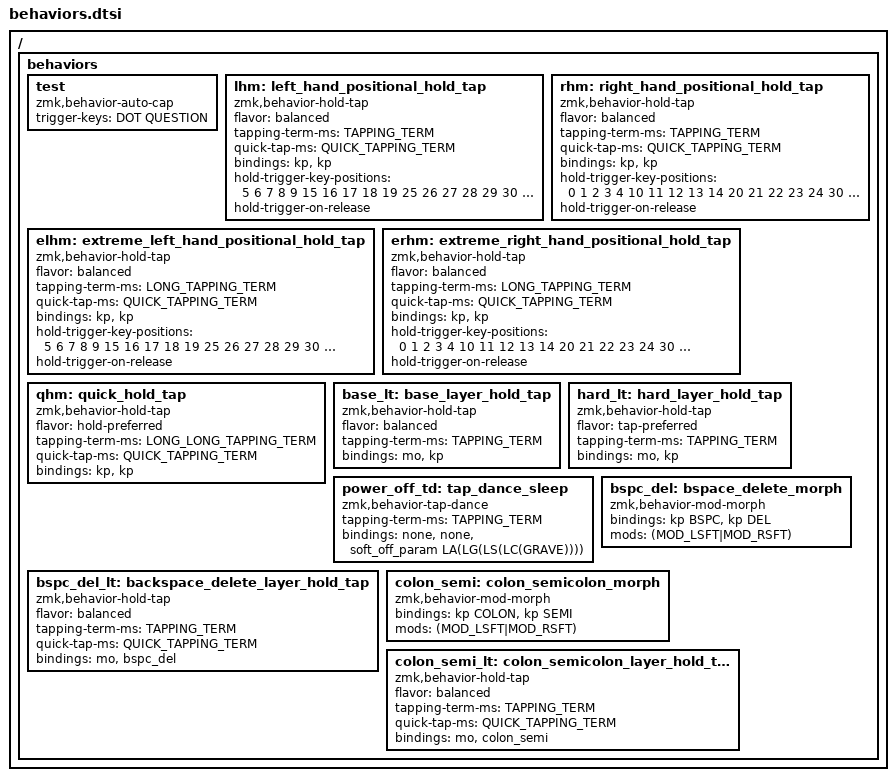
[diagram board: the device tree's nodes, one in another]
/*                KEY POSITIONS

	  ╭────────────────────╮ ╭────────────────────╮
	  │  0   1   2   3   4 │ │  5   6   7   8   9 │
	  │ 10  11  12  13  14 │ │ 15  16  17  18  19 │
	  │ 20  21  22  23  24 │ │ 25  26  27  28  29 │
	  ╰───────╮ 30  31  32 │ │ 33  34  35 ╭───────╯
      		  ╰────────────╯ ╰────────────╯          */

#define TAPPING_TERM 200
#define LONG_TAPPING_TERM 250
#define QUICK_TAPPING_TERM 0
#define LONG_LONG_TAPPING_TERM 500


/ {
	behaviors {
		test: test {
		    compatible = "zmk,behavior-auto-cap";
		    #binding-cells = <0>;
		    trigger-keys = <DOT QUESTION>;
		};

		lhm: left_hand_positional_hold_tap {
		    compatible = "zmk,behavior-hold-tap";
		    #binding-cells = <2>;
		    flavor = "balanced";
		    tapping-term-ms = <TAPPING_TERM>;
		    quick-tap-ms = <QUICK_TAPPING_TERM>;
		    bindings = <&kp>, <&kp>;
		    hold-trigger-key-positions = <5 6 7 8 9 15 16 17 18 19 25 26 27 28 29 30 31 32 33 34 35>;
        hold-trigger-on-release;
		};

		elhm: extreme_left_hand_positional_hold_tap {
		    compatible = "zmk,behavior-hold-tap";
		    #binding-cells = <2>;
		    flavor = "balanced";
		    tapping-term-ms = <LONG_TAPPING_TERM>;
		    quick-tap-ms = <QUICK_TAPPING_TERM>;
		    bindings = <&kp>, <&kp>;
		    hold-trigger-key-positions = <5 6 7 8 9 15 16 17 18 19 25 26 27 28 29 30 31 32 33 34 35>;
        hold-trigger-on-release;
		};

		rhm: right_hand_positional_hold_tap {
		    compatible = "zmk,behavior-hold-tap";
		    #binding-cells = <2>;
		    flavor = "balanced";
		    tapping-term-ms = <TAPPING_TERM>;
		    quick-tap-ms = <QUICK_TAPPING_TERM>;
		    bindings = <&kp>, <&kp>;
		    hold-trigger-key-positions = <0 1 2 3 4 10 11 12 13 14 20 21 22 23 24 30 31 32 33 34 35>;
        hold-trigger-on-release;
		};

		erhm: extreme_right_hand_positional_hold_tap {
		    compatible = "zmk,behavior-hold-tap";
		    #binding-cells = <2>;
		    flavor = "balanced";
		    tapping-term-ms = <LONG_TAPPING_TERM>;
		    quick-tap-ms = <QUICK_TAPPING_TERM>;
		    bindings = <&kp>, <&kp>;
		    hold-trigger-key-positions = <0 1 2 3 4 10 11 12 13 14 20 21 22 23 24 30 31 32 33 34 35>;
        hold-trigger-on-release;
		};

		qhm: quick_hold_tap {
		    compatible = "zmk,behavior-hold-tap";
		    #binding-cells = <2>;
		    flavor = "hold-preferred";
		    tapping-term-ms = <LONG_LONG_TAPPING_TERM>;
		    quick-tap-ms = <QUICK_TAPPING_TERM>;
		    bindings = <&kp>, <&kp>;
		};

		base_lt: base_layer_hold_tap {
		    compatible = "zmk,behavior-hold-tap";
		    #binding-cells = <2>;
		    flavor = "balanced";
		    tapping-term-ms = <TAPPING_TERM>;
		    bindings = <&mo>, <&kp>;
		};

		hard_lt: hard_layer_hold_tap {
		    compatible = "zmk,behavior-hold-tap";
		    #binding-cells = <2>;
		    flavor = "tap-preferred";
		    tapping-term-ms = <TAPPING_TERM>;
		    bindings = <&mo>, <&kp>;
		};

		power_off_td: tap_dance_sleep {
		    compatible = "zmk,behavior-tap-dance";
		    #binding-cells = <0>;
		    tapping-term-ms = <TAPPING_TERM>;
		    bindings = <&none>, <&none>, <&soft_off_param LA(LG(LS(LC(GRAVE))))>;
		};

		bspc_del: bspace_delete_morph {
		    compatible = "zmk,behavior-mod-morph";
		    #binding-cells = <0>;
		    bindings = <&kp BSPC>, <&kp DEL>;
		    mods = <(MOD_LSFT|MOD_RSFT)>;
		};

		bspc_del_lt: backspace_delete_layer_hold_tap {
		    compatible = "zmk,behavior-hold-tap";
		    #binding-cells = <2>;
		    flavor = "balanced";
		    tapping-term-ms = <TAPPING_TERM>;
		    quick-tap-ms = <QUICK_TAPPING_TERM>;
		    bindings = <&mo>, <&bspc_del>;
		};

		colon_semi: colon_semicolon_morph {
		    compatible = "zmk,behavior-mod-morph";
		    #binding-cells = <0>;
		    bindings = <&kp COLON>, <&kp SEMI>;
		    mods = <(MOD_LSFT|MOD_RSFT)>;
		};

		colon_semi_lt: colon_semicolon_layer_hold_tap {
		    compatible = "zmk,behavior-hold-tap";
		    #binding-cells = <2>;
		    flavor = "balanced";
		    tapping-term-ms = <TAPPING_TERM>;
		    quick-tap-ms = <QUICK_TAPPING_TERM>;
		    bindings = <&mo>, <&colon_semi>;
		};
	};
};
